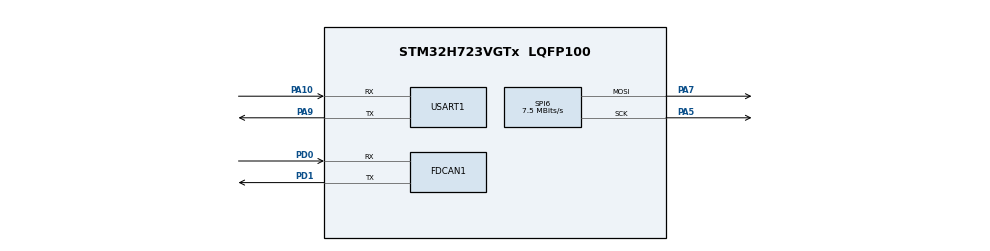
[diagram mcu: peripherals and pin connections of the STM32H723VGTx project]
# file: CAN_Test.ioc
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FDCAN1.AutoRetransmission=DISABLE
FDCAN1.CalculateBaudRateNominal=1000000
FDCAN1.CalculateTimeBitNominal=1000
FDCAN1.CalculateTimeQuantumNominal=25.0
FDCAN1.Mode=FDCAN_MODE_NORMAL
FDCAN1.NominalPrescaler=3
FDCAN1.NominalTimeSeg1=29
FDCAN1.NominalTimeSeg2=10
FDCAN1.RxFifo0ElmtsNbr=8
FDCAN1.RxFifo1ElmtsNbr=8
FDCAN1.StdFiltersNbr=1
FDCAN1.TxFifoQueueElmtsNbr=8
Mcu.Family=STM32H7
Mcu.Name=STM32H723VGTx
Mcu.Package=LQFP100
NVIC.FDCAN1_IT0_IRQn=true\:0\:0\:false\:false\:true\:true\:true\:true
NVIC.PriorityGroup=NVIC_PRIORITYGROUP_4
NVIC.TIM5_IRQn=true\:0\:0\:false\:false\:true\:true\:true\:true
NVIC.TIM6_DAC_IRQn=true\:0\:0\:false\:false\:true\:true\:true\:true
PA10.Mode=Asynchronous
PA10.Signal=USART1_RX
PA5.Mode=TX_Only_Simplex_Unidirect_Master
PA5.Signal=SPI6_SCK
PA7.GPIO_Speed=GPIO_SPEED_FREQ_VERY_HIGH
PA7.Mode=TX_Only_Simplex_Unidirect_Master
PA7.Signal=SPI6_MOSI
PA9.Mode=Asynchronous
PA9.Signal=USART1_TX
PD0.Mode=FDCAN_Activate
PD0.Signal=FDCAN1_RX
PD1.Mode=FDCAN_Activate
PD1.Signal=FDCAN1_TX
PH0-OSC_IN.Mode=HSE-External-Oscillator
PH0-OSC_IN.Signal=RCC_OSC_IN
PH1-OSC_OUT.Mode=HSE-External-Oscillator
PH1-OSC_OUT.Signal=RCC_OSC_OUT
ProjectManager.HeapSize=0x200
ProjectManager.StackSize=0x400
ProjectManager.TargetToolchain=CMake
RCC.ADCFreq_Value=48375000
RCC.APB1Freq_Value=60000000
RCC.APB2Freq_Value=60000000
RCC.APB3Freq_Value=60000000
RCC.APB4Freq_Value=60000000
RCC.CortexFreq_Value=240000000
RCC.D1CPRE=RCC_SYSCLK_DIV2
RCC.D1PPRE=RCC_APB3_DIV4
RCC.D2PPRE1=RCC_APB1_DIV4
RCC.D2PPRE2=RCC_APB2_DIV4
RCC.D3PPRE=RCC_APB4_DIV4
RCC.DIVM1=4
RCC.DIVN1=80
RCC.DIVP1=1
RCC.DIVQ1=4
RCC.HCLKFreq_Value=240000000
RCC.HSE_VALUE=24000000
RCC.PLL1_VCI_Range=RCC_PLL1VCIRANGE_3
RCC.PLLFRACN=0
RCC.PLLSourceVirtual=RCC_PLLSOURCE_HSE
RCC.SYSCLKFreq_VALUE=480000000
RCC.SYSCLKSource=RCC_SYSCLKSOURCE_PLLCLK
RCC.USBFreq_Value=120000000
SPI6.BaudRatePrescaler=SPI_BAUDRATEPRESCALER_8
SPI6.CalculateBaudRate=7.5 MBits/s
SPI6.DataSize=SPI_DATASIZE_8BIT
SPI6.Direction=SPI_DIRECTION_2LINES_TXONLY
SPI6.Mode=SPI_MODE_MASTER
SPI6.VirtualType=VM_MASTER
TIM5.Period=3599999999
TIM5.Prescaler=119
TIM6.Period=999
TIM6.Prescaler=119
USART1.VirtualMode-Asynchronous=VM_ASYNC
VP_MEMORYMAP_VS_MEMORYMAP.Mode=CurAppReg
VP_TIM5_VS_ClockSourceINT.Mode=Internal
VP_TIM6_VS_ClockSourceINT.Mode=Enable_Timer
board=custom

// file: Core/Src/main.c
/* USER CODE BEGIN Header */
/**
  ******************************************************************************
  * @file           : main.c
  * @brief          : Main program body
  ******************************************************************************
  * @attention
  *
  * Copyright (c) 2026 STMicroelectronics.
  * All rights reserved.
  *
  * This software is licensed under terms that can be found in the LICENSE file
  * in the root directory of this software component.
  * If no LICENSE file comes with this software, it is provided AS-IS.
  *
  ******************************************************************************
  */
/* USER CODE END Header */
#include "main.h"
#include "fdcan.h"
#include "spi.h"
#include "tim.h"
#include "usart.h"
#include "gpio.h"

/* USER CODE BEGIN Includes */

#include "app.h"
#include "motor6623.h"
extern Motor6623 motor;

/* USER CODE END Includes */

void SystemClock_Config(void);

int main(void)
{

  /* MCU Configuration--------------------------------------------------------*/

  /* Reset of all peripherals, Initializes the Flash interface and the Systick. */
  HAL_Init();

  /* Configure the system clock */
  SystemClock_Config();

  /* Initialize all configured peripherals */
  MX_GPIO_Init();
  MX_FDCAN1_Init();
  MX_SPI6_Init();
  MX_TIM5_Init();
  MX_TIM6_Init();
  MX_USART1_UART_Init();
  /* USER CODE BEGIN 2 */
  App_CAN_Init();
  uint32_t last_log = 0;
  /* USER CODE END 2 */

  /* Infinite loop */
  /* USER CODE BEGIN WHILE */
  while (1)
  {
    uint32_t now = HAL_GetTick();

    App_Task_Position_Step();

    if (now - last_log >=5) {
      last_log = now;
      App_Log_Task();
    }

    /* USER CODE END WHILE */

  }
}

void SystemClock_Config(void)
{
  RCC_OscInitTypeDef RCC_OscInitStruct = {0};
  RCC_ClkInitTypeDef RCC_ClkInitStruct = {0};

  /** Supply configuration update enable
  */
  HAL_PWREx_ConfigSupply(PWR_LDO_SUPPLY);

  /** Configure the main internal regulator output voltage
  */
  __HAL_PWR_VOLTAGESCALING_CONFIG(PWR_REGULATOR_VOLTAGE_SCALE0);

  while(!__HAL_PWR_GET_FLAG(PWR_FLAG_VOSRDY)) {}

  /** Initializes the RCC Oscillators according to the specified parameters
  * in the RCC_OscInitTypeDef structure.
  */
  RCC_OscInitStruct.OscillatorType = RCC_OSCILLATORTYPE_HSE;
  RCC_OscInitStruct.HSEState = RCC_HSE_ON;
  RCC_OscInitStruct.PLL.PLLState = RCC_PLL_ON;
  RCC_OscInitStruct.PLL.PLLSource = RCC_PLLSOURCE_HSE;
  RCC_OscInitStruct.PLL.PLLM = 4;
  RCC_OscInitStruct.PLL.PLLN = 80;
  RCC_OscInitStruct.PLL.PLLP = 1;
  RCC_OscInitStruct.PLL.PLLQ = 4;
  RCC_OscInitStruct.PLL.PLLR = 2;
  RCC_OscInitStruct.PLL.PLLRGE = RCC_PLL1VCIRANGE_3;
  RCC_OscInitStruct.PLL.PLLVCOSEL = RCC_PLL1VCOWIDE;
  RCC_OscInitStruct.PLL.PLLFRACN = 0;
  if (HAL_RCC_OscConfig(&RCC_OscInitStruct) != HAL_OK)
  {
    Error_Handler();
  }

  /** Initializes the CPU, AHB and APB buses clocks
  */
  RCC_ClkInitStruct.ClockType = RCC_CLOCKTYPE_HCLK|RCC_CLOCKTYPE_SYSCLK
                              |RCC_CLOCKTYPE_PCLK1|RCC_CLOCKTYPE_PCLK2
                              |RCC_CLOCKTYPE_D3PCLK1|RCC_CLOCKTYPE_D1PCLK1;
  RCC_ClkInitStruct.SYSCLKSource = RCC_SYSCLKSOURCE_PLLCLK;
  RCC_ClkInitStruct.SYSCLKDivider = RCC_SYSCLK_DIV2;
  RCC_ClkInitStruct.AHBCLKDivider = RCC_HCLK_DIV1;
  RCC_ClkInitStruct.APB3CLKDivider = RCC_APB3_DIV4;
  RCC_ClkInitStruct.APB1CLKDivider = RCC_APB1_DIV4;
  RCC_ClkInitStruct.APB2CLKDivider = RCC_APB2_DIV4;
  RCC_ClkInitStruct.APB4CLKDivider = RCC_APB4_DIV4;

  if (HAL_RCC_ClockConfig(&RCC_ClkInitStruct, FLASH_LATENCY_3) != HAL_OK)
  {
    Error_Handler();
  }
}

void Error_Handler(void)
{
  __disable_irq();
  while (1)
  {
  }
}
